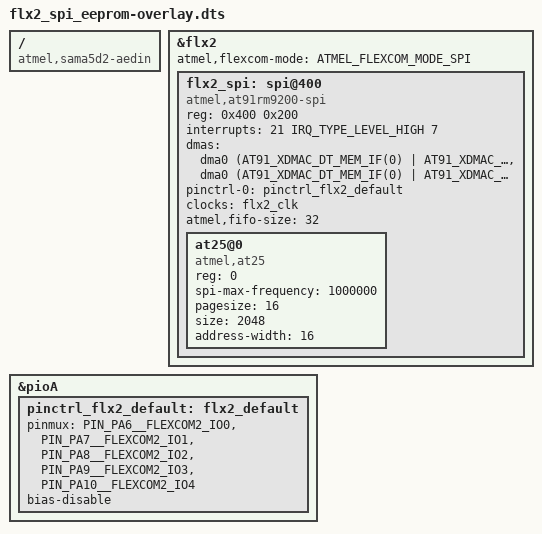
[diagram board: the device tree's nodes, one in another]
/*
 * Device Tree overlay for the AEMICS DIN module processing board
 *
 * Adds AT25 compatible EEPROM on flx2_spi
 *
 *  Copyright (C) 2016 AEMICS
 */
/dts-v1/;
/plugin/;

#include "../sama5d2-pinfunc.h"
#include <dt-bindings/mfd/atmel-flexcom.h>
#include <dt-bindings/gpio/gpio.h>
#include <dt-bindings/dma/at91.h>
#include <dt-bindings/interrupt-controller/irq.h>
#include <dt-bindings/clock/at91.h>

/{
	compatible = "atmel,sama5d2-aedin", "atmel,sama5d2", "atmel,sama5";

	fragment@0 {
		target = <&flx2>;
		__overlay__ {
			#address-cells = <1>;
			#size-cells = <1>;
			atmel,flexcom-mode = <ATMEL_FLEXCOM_MODE_SPI>;
			status = "okay";
			flx2_spi: spi@400 {
				compatible = "atmel,at91rm9200-spi";
				reg = <0x400 0x200>;
				interrupts = <21 IRQ_TYPE_LEVEL_HIGH 7>;
				dmas = <&dma0
				(AT91_XDMAC_DT_MEM_IF(0) | AT91_XDMAC_DT_PER_IF(1) |
				 AT91_XDMAC_DT_PERID(15))>,
				   <&dma0
				(AT91_XDMAC_DT_MEM_IF(0) | AT91_XDMAC_DT_PER_IF(1) |
				 AT91_XDMAC_DT_PERID(16))>;
				dma-names = "tx", "rx";
				pinctrl-names = "default";
				pinctrl-0 = <&pinctrl_flx2_default>;
				#address-cells = <1>;
				#size-cells = <0>;
				clocks = <&flx2_clk>;
				clock-names = "spi_clk";
				atmel,fifo-size = <32>;
				status = "okay";
				
				at25@0 {
					compatible = "atmel,at25";
					reg = <0>;
					spi-max-frequency = <1000000>;
					pagesize = <16>;
					size = <2048>;
					address-width = <16>;
				};
			};
		};
	};
	
	fragment@1 {
		target = <&pioA>;
		__overlay__ {
			pinctrl_flx2_default: flx2_default {
				pinmux = <PIN_PA6__FLEXCOM2_IO0>,
					 <PIN_PA7__FLEXCOM2_IO1>,
					 <PIN_PA8__FLEXCOM2_IO2>,
					 <PIN_PA9__FLEXCOM2_IO3>,
					 <PIN_PA10__FLEXCOM2_IO4>;
				bias-disable;
			};
		};
	};
};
